# DSC28027 register map
Vendor: Beijing Haawking Technology Co.,Ltd.; File version: 1.0
Registers are 32-bit, read-write, reset 0x0 unless marked. A register's access mark holds for its fields unless they carry their own. Offsets are from the block's base; [hi:lo] are bit positions; {n}, {i} and the like mark numbered series; 'fields as' and 'values as' point back to an identical list.

## SPI2 — Serial Peripheral Interface 2 (slave)
Base 0x50240000
Same registers: OTP 0x50420000
0x00 dummy — Dummy register: this peripheral is not implemented yet

## APU — Audio Processor
Base 0x50250200
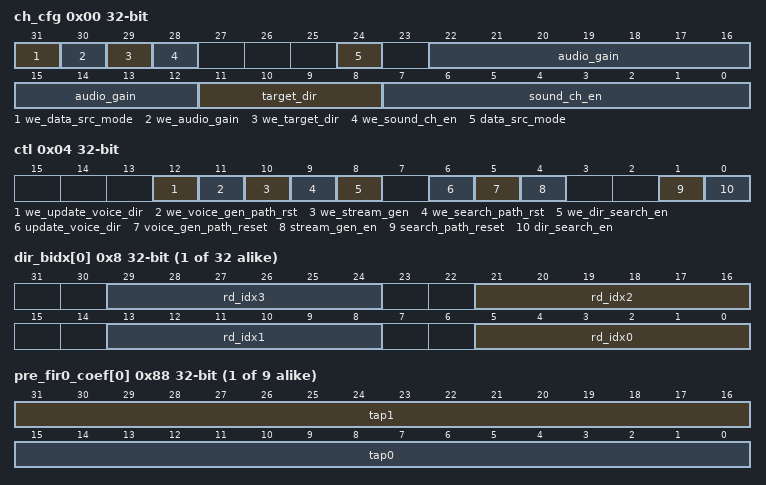
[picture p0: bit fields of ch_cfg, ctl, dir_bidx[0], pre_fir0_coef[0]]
0x00 ch_cfg — Channel Config Register
  [31] we_data_src_mode wo — Write enable for data_out_mode parameter
  [30] we_audio_gain wo — Write enable for audio_gain parameter
  [29] we_target_dir wo — Write enable for target_dir parameter
  [28] we_sound_ch_en wo — Write enable for sound_ch_en parameter
  [24] data_src_mode — Audio data source configure parameter
  [22:12] audio_gain — Audio sample gain factor
  [11:8] target_dir — Target direction select for valid voice output
  [7:0] sound_ch_en — BF unit sound channel enable control bits
0x04 ctl — Control Register
  [12] we_update_voice_dir wo — Write enable for we_update_voice_dir parameter
  [11] we_voice_gen_path_rst wo — Write enable for we_voice_gen_path_rst parameter
  [10] we_stream_gen wo — Write enable for we_stream_gen parameter
  [9] we_search_path_rst wo — Write enable for we_search_path_rst parameter
  [8] we_dir_search_en wo — Write enable for we_dir_search_en parameter
  [6] update_voice_dir — Switch to a new voice source direction
  [5] voice_gen_path_reset — Reset all control logic on voice stream generating path
  [4] stream_gen_en — Valid voice sample stream generation enable bit
  [1] search_path_reset — Reset all control logic on direction search processing path
  [0] dir_search_en — Sound direction searching enable bit
{0x8+4i} dir_bidx[{i}] (i=0..31) — Direction Sample Buffer Read Index Configure Register (16 directions * 2 values * 4 indices)
  [8n+5:8n] rd_idx{n} (n=0..3) — rd_idx{n}
{0x88+4i} pre_fir0_coef[{i}] (i=0..8) — FIR0 pre-filter coefficients
  [31:16] tap1, [15:0] tap0
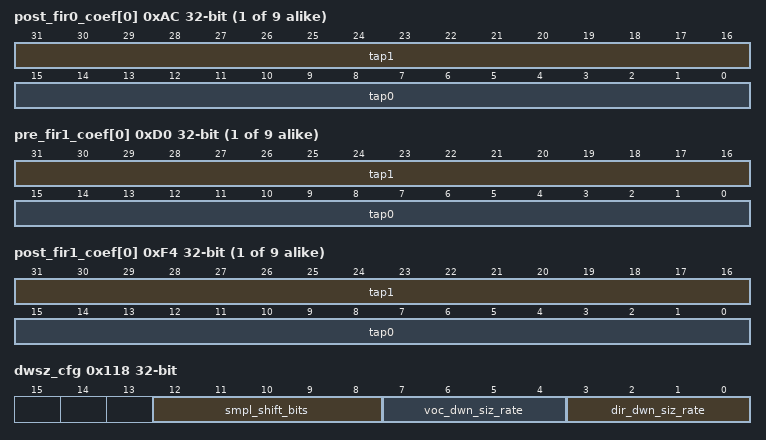
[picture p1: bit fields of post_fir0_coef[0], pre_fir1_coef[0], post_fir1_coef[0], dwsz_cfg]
{0xAC+4i} post_fir0_coef[{i}] (i=0..8) — FIR0 post-filter coefficients
  [31:16] tap1, [15:0] tap0
{0xD0+4i} pre_fir1_coef[{i}] (i=0..8) — FIR1 pre-filter coeffecients
  [31:16] tap1, [15:0] tap0
{0xF4+4i} post_fir1_coef[{i}] (i=0..8) — FIR1 post-filter coefficients
  [31:16] tap1, [15:0] tap0
0x118 dwsz_cfg — Downsize Config Register
  [12:8] smpl_shift_bits — Sample precision reduction when the source sound sample precision is 20/24/32 bits
  [7:4] voc_dwn_siz_rate — Down-sizing ratio used for voice stream generation
  [3:0] dir_dwn_siz_rate — Down-sizing ratio used for direction searching
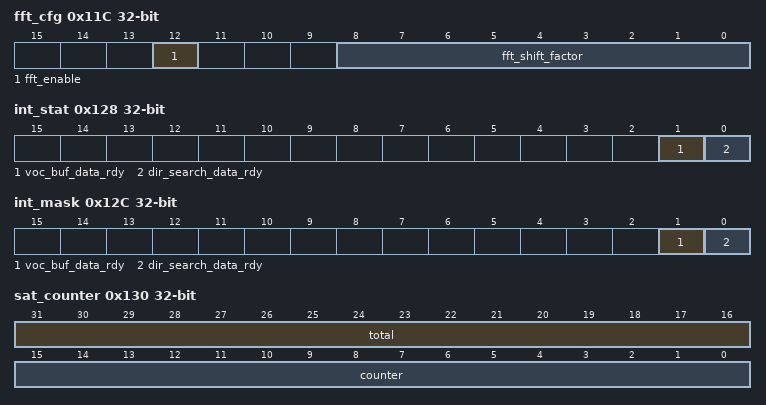
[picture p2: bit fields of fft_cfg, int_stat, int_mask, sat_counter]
0x11C fft_cfg — FFT Config Register
  [12] fft_enable, [8:0] fft_shift_factor
0x120 sobuf_dma_rdata — Read register for DMA to sample-out buffers
0x124 vobuf_dma_rdata — Read register for DMA to voice-out buffers
0x128 int_stat — Interrupt Status Register
  [1] voc_buf_data_rdy — Voice output stream buffer data ready interrupt event
  [0] dir_search_data_rdy — Sound direction searching data ready interrupt event
0x12C int_mask — Interrupt Mask Register
  fields as int_stat
0x130 sat_counter — Saturation Counter
  [31:16] total, [15:0] counter
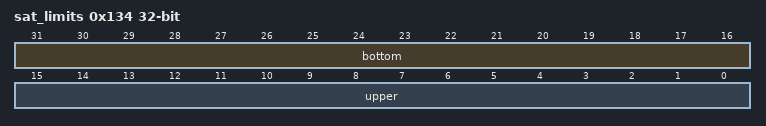
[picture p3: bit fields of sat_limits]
0x134 sat_limits — Saturation Limits
  [31:16] bottom — Bottom limit
  [15:0] upper — Upper limit

## FPIOA — Field Programmable IO Array
Base 0x502B0000
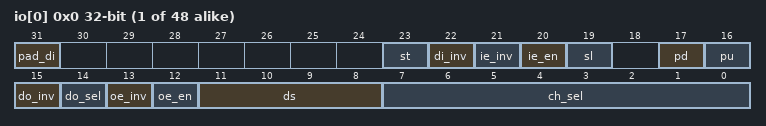
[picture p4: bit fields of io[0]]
{0x0+4i} io[{i}] (i=0..47) — FPIOA GPIO multiplexer io array
  [31] pad_di — Read current IO's data input
  [23] st — Schmitt trigger
  [22] di_inv — Invert Data input
  [21] ie_inv — Invert input enable
  [20] ie_en — Static input enable, will AND with IE_INV
  [19] sl — Slew rate control enable
  [17] pd — Pull down enable. 0 for nothing, 1 for pull down
  [16] pu — Pull up enable. 0 for nothing, 1 for pull up
  [15] do_inv — Invert the result of data output select (DO_SEL)
  [14] do_sel — Data output select: 0 for DO, 1 for OE
  [13] oe_inv — Invert output enable
  [12] oe_en — Static output enable, will AND with OE_INV
  [11:8] ds — Driving selector
  [7:0] ch_sel — Channel select from 256 input
{0xC0+4i} tie_en[{i}] (i=0..7) — FPIOA GPIO multiplexer tie enable array
{0xE0+4i} tie_val[{i}] (i=0..7) — FPIOA GPIO multiplexer tie value array
